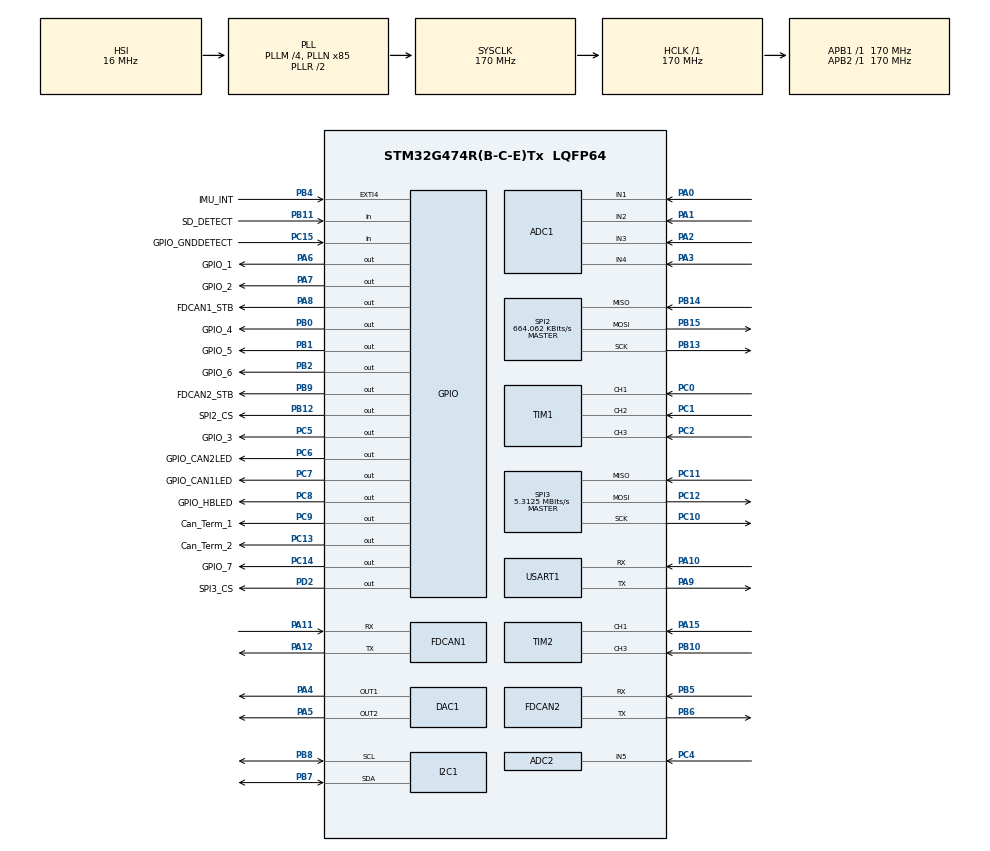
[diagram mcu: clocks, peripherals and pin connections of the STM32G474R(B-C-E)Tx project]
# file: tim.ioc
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ADC1.Channel-0\#ChannelRegularConversion=ADC_CHANNEL_1
ADC1.NbrOfConversionFlag=1
ADC1.OffsetNumber-0\#ChannelRegularConversion=ADC_OFFSET_NONE
ADC1.Rank-0\#ChannelRegularConversion=1
ADC1.SamplingTime-0\#ChannelRegularConversion=ADC_SAMPLETIME_2CYCLES_5
ADC1.master=1
ADC2.Channel-2\#ChannelRegularConversion=ADC_CHANNEL_5
ADC2.NbrOfConversionFlag=1
ADC2.OffsetNumber-2\#ChannelRegularConversion=ADC_OFFSET_NONE
ADC2.Rank-2\#ChannelRegularConversion=1
ADC2.SamplingTime-2\#ChannelRegularConversion=ADC_SAMPLETIME_2CYCLES_5
DAC1.DAC_Channel-DAC_OUT2=DAC_CHANNEL_2
FDCAN1.AutoRetransmission=ENABLE
FDCAN1.CalculateBaudRateNominal=500000
FDCAN1.CalculateTimeBitNominal=2000
FDCAN1.CalculateTimeQuantumNominal=100.0
FDCAN1.DataPrescaler=5
FDCAN1.DataSyncJumpWidth=3
FDCAN1.DataTimeSeg1=13
FDCAN1.DataTimeSeg2=3
FDCAN1.FrameFormat=FDCAN_FRAME_FD_BRS
FDCAN1.NominalPrescaler=17
FDCAN1.NominalSyncJumpWidth=4
FDCAN1.NominalTimeSeg1=15
FDCAN1.NominalTimeSeg2=4
FDCAN2.AutoRetransmission=ENABLE
FDCAN2.CalculateBaudRateNominal=500000
FDCAN2.CalculateTimeBitNominal=2000
FDCAN2.CalculateTimeQuantumNominal=100.0
FDCAN2.DataPrescaler=5
FDCAN2.DataSyncJumpWidth=3
FDCAN2.DataTimeSeg1=13
FDCAN2.DataTimeSeg2=3
FDCAN2.FrameFormat=FDCAN_FRAME_FD_BRS
FDCAN2.NominalPrescaler=17
FDCAN2.NominalSyncJumpWidth=4
FDCAN2.NominalTimeSeg1=15
FDCAN2.NominalTimeSeg2=4
FREERTOS.Tasks01=initTask,24,128,StartDefaultTask,Default,NULL,Dynamic,NULL,NULL
FREERTOS.configTOTAL_HEAP_SIZE=32768
FREERTOS.configUSE_NEWLIB_REENTRANT=1
I2C1.Timing=0x40B285C2
Mcu.Family=STM32G4
Mcu.Name=STM32G474R(B-C-E)Tx
Mcu.Package=LQFP64
NVIC.EXTI4_IRQn=true\:5\:0\:false\:false\:true\:true\:true\:true\:true
NVIC.FDCAN1_IT0_IRQn=true\:5\:0\:false\:false\:true\:true\:true\:true\:true
NVIC.FDCAN1_IT1_IRQn=true\:5\:0\:false\:false\:true\:true\:true\:true\:true
NVIC.FDCAN2_IT0_IRQn=true\:5\:0\:false\:false\:true\:true\:true\:true\:true
NVIC.FDCAN2_IT1_IRQn=true\:5\:0\:false\:false\:true\:true\:true\:true\:true
NVIC.PriorityGroup=NVIC_PRIORITYGROUP_4
NVIC.TIM6_DAC_IRQn=true\:15\:0\:false\:false\:true\:false\:false\:true\:true
NVIC.TimeBase=TIM6_DAC_IRQn
NVIC.TimeBaseIP=TIM6
NVIC.USART1_IRQn=true\:5\:0\:false\:false\:true\:true\:true\:true\:true
PA0.Mode=IN1-Single-Ended
PA0.Signal=ADC1_IN1
PA1.Mode=IN2-Single-Ended
PA1.Signal=ADC1_IN2
PA10.Mode=Asynchronous
PA10.Signal=USART1_RX
PA11.Mode=FDCAN_Activate
PA11.Signal=FDCAN1_RX
PA12.Mode=FDCAN_Activate
PA12.Signal=FDCAN1_TX
PA13.GPIO_Label=SWDIO
PA13.Mode=Trace_Asynchronous_SW
PA13.Signal=SYS_JTMS-SWDIO
PA14.GPIO_Label=SWCLK
PA14.Mode=Trace_Asynchronous_SW
PA14.Signal=SYS_JTCK-SWCLK
PA15.Signal=S_TIM2_CH1
PA2.Mode=IN3-Single-Ended
PA2.Signal=ADC1_IN3
PA3.Mode=IN4-Single-Ended
PA3.Signal=ADC1_IN4
PA4.Signal=COMP_DAC11_group
PA5.Signal=COMP_DAC12_group
PA6.GPIO_Label=GPIO_1
PA6.Signal=GPIO_Output
PA7.GPIO_Label=GPIO_2
PA7.Signal=SharedStack_PA7
PA8.GPIO_Label=FDCAN1_STB
PA8.PinState=GPIO_PIN_SET
PA8.Signal=GPIO_Output
PA9.Mode=Asynchronous
PA9.Signal=USART1_TX
PB0.GPIO_Label=GPIO_4
PB0.Signal=SharedStack_PB0
PB1.GPIO_Label=GPIO_5
PB1.Signal=SharedStack_PB1
PB10.Signal=S_TIM2_CH3
PB11.GPIO_Label=SD_DETECT
PB11.GPIO_PuPd=GPIO_PULLUP
PB11.Signal=GPIO_Input
PB12.GPIO_Label=SPI2_CS
PB12.PinState=GPIO_PIN_SET
PB12.Signal=GPIO_Output
PB13.Mode=Full_Duplex_Master
PB13.Signal=SPI2_SCK
PB14.Mode=Full_Duplex_Master
PB14.Signal=SPI2_MISO
PB15.Mode=Full_Duplex_Master
PB15.Signal=SPI2_MOSI
PB2.GPIO_Label=GPIO_6
PB2.Signal=SharedStack_PB2
PB3.GPIO_Label=SWO
PB3.Mode=Trace_Asynchronous_SW
PB3.Signal=SYS_JTDO-SWO
PB4.GPIO_Label=IMU_INT
PB4.Signal=GPXTI4
PB5.Mode=FDCAN_Activate
PB5.Signal=FDCAN2_RX
PB6.Mode=FDCAN_Activate
PB6.Signal=FDCAN2_TX
PB7.Mode=I2C
PB7.Signal=I2C1_SDA
PB8-BOOT0.Mode=I2C
PB8-BOOT0.Signal=I2C1_SCL
PB9.GPIO_Label=FDCAN2_STB
PB9.PinState=GPIO_PIN_SET
PB9.Signal=GPIO_Output
PC0.Signal=S_TIM1_CH1
PC1.Signal=S_TIM1_CH2
PC10.Mode=Full_Duplex_Master
PC10.Signal=SPI3_SCK
PC11.Mode=Full_Duplex_Master
PC11.Signal=SPI3_MISO
PC12.Mode=Full_Duplex_Master
PC12.Signal=SPI3_MOSI
PC13.GPIO_Label=Can_Term_2
PC13.Signal=GPIO_Output
PC14-OSC32_IN.GPIO_Label=GPIO_7
PC14-OSC32_IN.Signal=GPIO_Output
PC15-OSC32_OUT.GPIO_Label=GPIO_GNDDETECT
PC15-OSC32_OUT.GPIO_PuPd=GPIO_PULLUP
PC15-OSC32_OUT.Signal=GPIO_Input
PC2.Signal=S_TIM1_CH3
PC3.GPIO_Label=VBAT_ADC
PC3.Signal=ADC1_IN9
PC4.Mode=IN5-Single-Ended
PC4.Signal=ADC2_IN5
PC5.GPIO_Label=GPIO_3
PC5.Signal=SharedStack_PC5
PC6.GPIO_Label=GPIO_CAN2LED
PC6.GPIO_ModeDefaultOutputPP=GPIO_MODE_OUTPUT_PP
PC6.GPIO_PuPd=GPIO_NOPULL
PC6.PinState=GPIO_PIN_SET
PC6.Signal=GPIO_Output
PC7.GPIO_Label=GPIO_CAN1LED
PC7.GPIO_ModeDefaultOutputPP=GPIO_MODE_OUTPUT_PP
PC7.GPIO_PuPd=GPIO_NOPULL
PC7.PinState=GPIO_PIN_SET
PC7.Signal=GPIO_Output
PC8.GPIO_Label=GPIO_HBLED
PC8.GPIO_ModeDefaultOutputPP=GPIO_MODE_OUTPUT_PP
PC8.GPIO_PuPd=GPIO_NOPULL
PC8.PinState=GPIO_PIN_SET
PC8.Signal=GPIO_Output
PC9.GPIO_Label=Can_Term_1
PC9.Signal=GPIO_Output
PD2.GPIO_Label=SPI3_CS
PD2.PinState=GPIO_PIN_SET
PD2.Signal=GPIO_Output
PF0-OSC_IN.Mode=HSE-External-Oscillator
PF0-OSC_IN.Signal=RCC_OSC_IN
PF1-OSC_OUT.Mode=HSE-External-Oscillator
PF1-OSC_OUT.Signal=RCC_OSC_OUT
ProjectManager.HeapSize=0x200
ProjectManager.StackSize=0x400
ProjectManager.TargetToolchain=CMake
RCC.ADC12Freq_Value=170000000
RCC.ADC345Freq_Value=170000000
RCC.AHBFreq_Value=170000000
RCC.APB1Freq_Value=170000000
RCC.APB1TimFreq_Value=170000000
RCC.APB2Freq_Value=170000000
RCC.APB2TimFreq_Value=170000000
RCC.CortexFreq_Value=170000000
RCC.EXTERNAL_CLOCK_VALUE=12288000
RCC.HCLKFreq_Value=170000000
RCC.HSE_VALUE=8000000
RCC.HSI48_VALUE=48000000
RCC.HSI_VALUE=16000000
RCC.LSE_VALUE=32768
RCC.PLLM=RCC_PLLM_DIV4
RCC.PLLN=85
RCC.SYSCLKFreq_VALUE=170000000
RCC.SYSCLKSource=RCC_SYSCLKSOURCE_PLLCLK
RCC.USBFreq_Value=170000000
RCC.VCOOutputFreq_Value=340000000
SH.COMP_DAC11_group.0=DAC1_OUT1,DAC_OUT1
SH.COMP_DAC12_group.0=DAC1_OUT2,DAC_OUT2
SH.S_TIM1_CH1.0=TIM1_CH1,Encoder_Interface
SH.S_TIM1_CH2.0=TIM1_CH2,Encoder_Interface
SH.S_TIM1_CH3.0=TIM1_CH3,Input_Capture3_from_TI3
SH.S_TIM2_CH1.0=TIM2_CH1,Input_Capture1_from_TI1
SH.S_TIM2_CH3.0=TIM2_CH3,Input_Capture3_from_TI3
SH.SharedStack_PA7.0=GPIO_Output
SH.SharedStack_PB0.0=GPIO_Output
SH.SharedStack_PB1.0=GPIO_Output
SH.SharedStack_PB2.0=GPIO_Output
SH.SharedStack_PC5.0=GPIO_Output
SPI2.BaudRatePrescaler=SPI_BAUDRATEPRESCALER_256
SPI2.CalculateBaudRate=664.062 KBits/s
SPI2.DataSize=SPI_DATASIZE_8BIT
SPI2.Direction=SPI_DIRECTION_2LINES
SPI2.Mode=SPI_MODE_MASTER
SPI2.VirtualType=VM_MASTER
SPI3.BaudRatePrescaler=SPI_BAUDRATEPRESCALER_32
SPI3.CLKPhase=SPI_PHASE_2EDGE
SPI3.CLKPolarity=SPI_POLARITY_HIGH
SPI3.CalculateBaudRate=5.3125 MBits/s
SPI3.DataSize=SPI_DATASIZE_8BIT
SPI3.Direction=SPI_DIRECTION_2LINES
SPI3.Mode=SPI_MODE_MASTER
SPI3.VirtualType=VM_MASTER
TIM1.Channel-Input_Capture3_from_TI3=TIM_CHANNEL_3
TIM2.Channel-Input_Capture1_from_TI1=TIM_CHANNEL_1
TIM2.Channel-Input_Capture3_from_TI3=TIM_CHANNEL_3
USART1.VirtualMode-Asynchronous=VM_ASYNC
VP_FATFS_VS_Generic.Mode=User_defined
VP_FREERTOS_VS_CMSIS_V2.Mode=CMSIS_V2
VP_SYS_VS_DBSignals.Mode=DisableDeadBatterySignals
VP_SYS_VS_tim6.Mode=TIM6
board=custom

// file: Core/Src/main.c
/* USER CODE BEGIN Header */
/**
  ******************************************************************************
  * @file           : main.c
  * @brief          : Main program body
  ******************************************************************************
  * @attention
  *
  * Copyright (c) 2026 STMicroelectronics.
  * All rights reserved.
  *
  * This software is licensed under terms that can be found in the LICENSE file
  * in the root directory of this software component.
  * If no LICENSE file comes with this software, it is provided AS-IS.
  *
  ******************************************************************************
  */
/* USER CODE END Header */
#include "main.h"
#include "cmsis_os.h"
#include "app_fatfs.h"

/* USER CODE BEGIN Includes */
#include "tasks.h"
/* USER CODE END Includes */

ADC_HandleTypeDef hadc1;
ADC_HandleTypeDef hadc2;

DAC_HandleTypeDef hdac1;

FDCAN_HandleTypeDef hfdcan1;
FDCAN_HandleTypeDef hfdcan2;

I2C_HandleTypeDef hi2c1;

SPI_HandleTypeDef hspi2;
SPI_HandleTypeDef hspi3;

TIM_HandleTypeDef htim1;
TIM_HandleTypeDef htim2;

UART_HandleTypeDef huart1;

/* Definitions for initTask */
osThreadId_t initTaskHandle;
const osThreadAttr_t initTask_attributes = {
  .name = "initTask",
  .priority = (osPriority_t) osPriorityNormal,
  .stack_size = 128 * 4
};

void SystemClock_Config(void);
static void MX_GPIO_Init(void);
static void MX_ADC1_Init(void);
static void MX_ADC2_Init(void);
static void MX_DAC1_Init(void);
static void MX_FDCAN1_Init(void);
static void MX_FDCAN2_Init(void);
static void MX_I2C1_Init(void);
static void MX_SPI2_Init(void);
static void MX_SPI3_Init(void);
static void MX_TIM1_Init(void);
static void MX_TIM2_Init(void);
static void MX_USART1_UART_Init(void);
void StartDefaultTask(void *argument);

int main(void)
{

  /* MCU Configuration--------------------------------------------------------*/

  /* Reset of all peripherals, Initializes the Flash interface and the Systick. */
  HAL_Init();

  /* Configure the system clock */
  SystemClock_Config();

  /* Initialize all configured peripherals */
  MX_GPIO_Init();
  MX_ADC1_Init();
  MX_ADC2_Init();
  MX_DAC1_Init();
  MX_FDCAN1_Init();
  MX_FDCAN2_Init();
  MX_I2C1_Init();
  MX_SPI2_Init();
  MX_SPI3_Init();
  MX_TIM1_Init();
  MX_TIM2_Init();
  MX_USART1_UART_Init();
  if (MX_FATFS_Init() != APP_OK) {
    Error_Handler();
  }

  /* Init scheduler */
  osKernelInitialize();

  /* Create the thread(s) */
  /* creation of initTask */
  initTaskHandle = osThreadNew(StartDefaultTask, NULL, &initTask_attributes);

  /* Start scheduler */
  osKernelStart();

  /* We should never get here as control is now taken by the scheduler */

  /* Infinite loop */
  while (1)
  {

  }
}

void SystemClock_Config(void)
{
  RCC_OscInitTypeDef RCC_OscInitStruct = {0};
  RCC_ClkInitTypeDef RCC_ClkInitStruct = {0};

  /** Configure the main internal regulator output voltage
  */
  HAL_PWREx_ControlVoltageScaling(PWR_REGULATOR_VOLTAGE_SCALE1_BOOST);

  /** Initializes the RCC Oscillators according to the specified parameters
  * in the RCC_OscInitTypeDef structure.
  */
  RCC_OscInitStruct.OscillatorType = RCC_OSCILLATORTYPE_HSI;
  RCC_OscInitStruct.HSIState = RCC_HSI_ON;
  RCC_OscInitStruct.HSICalibrationValue = RCC_HSICALIBRATION_DEFAULT;
  RCC_OscInitStruct.PLL.PLLState = RCC_PLL_ON;
  RCC_OscInitStruct.PLL.PLLSource = RCC_PLLSOURCE_HSI;
  RCC_OscInitStruct.PLL.PLLM = RCC_PLLM_DIV4;
  RCC_OscInitStruct.PLL.PLLN = 85;
  RCC_OscInitStruct.PLL.PLLP = RCC_PLLP_DIV2;
  RCC_OscInitStruct.PLL.PLLQ = RCC_PLLQ_DIV2;
  RCC_OscInitStruct.PLL.PLLR = RCC_PLLR_DIV2;
  if (HAL_RCC_OscConfig(&RCC_OscInitStruct) != HAL_OK)
  {
    Error_Handler();
  }

  /** Initializes the CPU, AHB and APB buses clocks
  */
  RCC_ClkInitStruct.ClockType = RCC_CLOCKTYPE_HCLK|RCC_CLOCKTYPE_SYSCLK
                              |RCC_CLOCKTYPE_PCLK1|RCC_CLOCKTYPE_PCLK2;
  RCC_ClkInitStruct.SYSCLKSource = RCC_SYSCLKSOURCE_PLLCLK;
  RCC_ClkInitStruct.AHBCLKDivider = RCC_SYSCLK_DIV1;
  RCC_ClkInitStruct.APB1CLKDivider = RCC_HCLK_DIV1;
  RCC_ClkInitStruct.APB2CLKDivider = RCC_HCLK_DIV1;

  if (HAL_RCC_ClockConfig(&RCC_ClkInitStruct, FLASH_LATENCY_4) != HAL_OK)
  {
    Error_Handler();
  }
}

static void MX_ADC1_Init(void)
{

  ADC_MultiModeTypeDef multimode = {0};
  ADC_ChannelConfTypeDef sConfig = {0};

  /** Common config
  */
  hadc1.Instance = ADC1;
  hadc1.Init.ClockPrescaler = ADC_CLOCK_SYNC_PCLK_DIV4;
  hadc1.Init.Resolution = ADC_RESOLUTION_12B;
  hadc1.Init.DataAlign = ADC_DATAALIGN_RIGHT;
  hadc1.Init.GainCompensation = 0;
  hadc1.Init.ScanConvMode = ADC_SCAN_DISABLE;
  hadc1.Init.EOCSelection = ADC_EOC_SINGLE_CONV;
  hadc1.Init.LowPowerAutoWait = DISABLE;
  hadc1.Init.ContinuousConvMode = DISABLE;
  hadc1.Init.NbrOfConversion = 1;
  hadc1.Init.DiscontinuousConvMode = DISABLE;
  hadc1.Init.ExternalTrigConv = ADC_SOFTWARE_START;
  hadc1.Init.ExternalTrigConvEdge = ADC_EXTERNALTRIGCONVEDGE_NONE;
  hadc1.Init.DMAContinuousRequests = DISABLE;
  hadc1.Init.Overrun = ADC_OVR_DATA_PRESERVED;
  hadc1.Init.OversamplingMode = DISABLE;
  if (HAL_ADC_Init(&hadc1) != HAL_OK)
  {
    Error_Handler();
  }

  /** Configure the ADC multi-mode
  */
  multimode.Mode = ADC_MODE_INDEPENDENT;
  if (HAL_ADCEx_MultiModeConfigChannel(&hadc1, &multimode) != HAL_OK)
  {
    Error_Handler();
  }

  /** Configure Regular Channel
  */
  sConfig.Channel = ADC_CHANNEL_1;
  sConfig.Rank = ADC_REGULAR_RANK_1;
  sConfig.SamplingTime = ADC_SAMPLETIME_2CYCLES_5;
  sConfig.SingleDiff = ADC_SINGLE_ENDED;
  sConfig.OffsetNumber = ADC_OFFSET_NONE;
  sConfig.Offset = 0;
  if (HAL_ADC_ConfigChannel(&hadc1, &sConfig) != HAL_OK)
  {
    Error_Handler();
  }

}

static void MX_ADC2_Init(void)
{

  ADC_ChannelConfTypeDef sConfig = {0};

  /** Common config
  */
  hadc2.Instance = ADC2;
  hadc2.Init.ClockPrescaler = ADC_CLOCK_SYNC_PCLK_DIV4;
  hadc2.Init.Resolution = ADC_RESOLUTION_12B;
  hadc2.Init.DataAlign = ADC_DATAALIGN_RIGHT;
  hadc2.Init.GainCompensation = 0;
  hadc2.Init.ScanConvMode = ADC_SCAN_DISABLE;
  hadc2.Init.EOCSelection = ADC_EOC_SINGLE_CONV;
  hadc2.Init.LowPowerAutoWait = DISABLE;
  hadc2.Init.ContinuousConvMode = DISABLE;
  hadc2.Init.NbrOfConversion = 1;
  hadc2.Init.DiscontinuousConvMode = DISABLE;
  hadc2.Init.ExternalTrigConv = ADC_SOFTWARE_START;
  hadc2.Init.ExternalTrigConvEdge = ADC_EXTERNALTRIGCONVEDGE_NONE;
  hadc2.Init.DMAContinuousRequests = DISABLE;
  hadc2.Init.Overrun = ADC_OVR_DATA_PRESERVED;
  hadc2.Init.OversamplingMode = DISABLE;
  if (HAL_ADC_Init(&hadc2) != HAL_OK)
  {
    Error_Handler();
  }

  /** Configure Regular Channel
  */
  sConfig.Channel = ADC_CHANNEL_5;
  sConfig.Rank = ADC_REGULAR_RANK_1;
  sConfig.SamplingTime = ADC_SAMPLETIME_2CYCLES_5;
  sConfig.SingleDiff = ADC_SINGLE_ENDED;
  sConfig.OffsetNumber = ADC_OFFSET_NONE;
  sConfig.Offset = 0;
  if (HAL_ADC_ConfigChannel(&hadc2, &sConfig) != HAL_OK)
  {
    Error_Handler();
  }

}

static void MX_DAC1_Init(void)
{

  DAC_ChannelConfTypeDef sConfig = {0};

  /** DAC Initialization
  */
  hdac1.Instance = DAC1;
  if (HAL_DAC_Init(&hdac1) != HAL_OK)
  {
    Error_Handler();
  }

  /** DAC channel OUT1 config
  */
  sConfig.DAC_HighFrequency = DAC_HIGH_FREQUENCY_INTERFACE_MODE_AUTOMATIC;
  sConfig.DAC_DMADoubleDataMode = DISABLE;
  sConfig.DAC_SignedFormat = DISABLE;
  sConfig.DAC_SampleAndHold = DAC_SAMPLEANDHOLD_DISABLE;
  sConfig.DAC_Trigger = DAC_TRIGGER_NONE;
  sConfig.DAC_Trigger2 = DAC_TRIGGER_NONE;
  sConfig.DAC_OutputBuffer = DAC_OUTPUTBUFFER_ENABLE;
  sConfig.DAC_ConnectOnChipPeripheral = DAC_CHIPCONNECT_EXTERNAL;
  sConfig.DAC_UserTrimming = DAC_TRIMMING_FACTORY;
  if (HAL_DAC_ConfigChannel(&hdac1, &sConfig, DAC_CHANNEL_1) != HAL_OK)
  {
    Error_Handler();
  }

  /** DAC channel OUT2 config
  */
  if (HAL_DAC_ConfigChannel(&hdac1, &sConfig, DAC_CHANNEL_2) != HAL_OK)
  {
    Error_Handler();
  }

}

static void MX_FDCAN1_Init(void)
{

  hfdcan1.Instance = FDCAN1;
  hfdcan1.Init.ClockDivider = FDCAN_CLOCK_DIV1;
  hfdcan1.Init.FrameFormat = FDCAN_FRAME_FD_BRS;
  hfdcan1.Init.Mode = FDCAN_MODE_NORMAL;
  hfdcan1.Init.AutoRetransmission = ENABLE;
  hfdcan1.Init.TransmitPause = DISABLE;
  hfdcan1.Init.ProtocolException = DISABLE;
  hfdcan1.Init.NominalPrescaler = 17;
  hfdcan1.Init.NominalSyncJumpWidth = 4;
  hfdcan1.Init.NominalTimeSeg1 = 15;
  hfdcan1.Init.NominalTimeSeg2 = 4;
  hfdcan1.Init.DataPrescaler = 5;
  hfdcan1.Init.DataSyncJumpWidth = 3;
  hfdcan1.Init.DataTimeSeg1 = 13;
  hfdcan1.Init.DataTimeSeg2 = 3;
  hfdcan1.Init.StdFiltersNbr = 0;
  hfdcan1.Init.ExtFiltersNbr = 0;
  hfdcan1.Init.TxFifoQueueMode = FDCAN_TX_FIFO_OPERATION;
  if (HAL_FDCAN_Init(&hfdcan1) != HAL_OK)
  {
    Error_Handler();
  }

}

static void MX_FDCAN2_Init(void)
{

  hfdcan2.Instance = FDCAN2;
  hfdcan2.Init.ClockDivider = FDCAN_CLOCK_DIV1;
  hfdcan2.Init.FrameFormat = FDCAN_FRAME_FD_BRS;
  hfdcan2.Init.Mode = FDCAN_MODE_NORMAL;
  hfdcan2.Init.AutoRetransmission = ENABLE;
  hfdcan2.Init.TransmitPause = DISABLE;
  hfdcan2.Init.ProtocolException = DISABLE;
  hfdcan2.Init.NominalPrescaler = 17;
  hfdcan2.Init.NominalSyncJumpWidth = 4;
  hfdcan2.Init.NominalTimeSeg1 = 15;
  hfdcan2.Init.NominalTimeSeg2 = 4;
  hfdcan2.Init.DataPrescaler = 5;
  hfdcan2.Init.DataSyncJumpWidth = 3;
  hfdcan2.Init.DataTimeSeg1 = 13;
  hfdcan2.Init.DataTimeSeg2 = 3;
  hfdcan2.Init.StdFiltersNbr = 0;
  hfdcan2.Init.ExtFiltersNbr = 0;
  hfdcan2.Init.TxFifoQueueMode = FDCAN_TX_FIFO_OPERATION;
  if (HAL_FDCAN_Init(&hfdcan2) != HAL_OK)
  {
    Error_Handler();
  }

}

static void MX_I2C1_Init(void)
{

  hi2c1.Instance = I2C1;
  hi2c1.Init.Timing = 0x40B285C2;
  hi2c1.Init.OwnAddress1 = 0;
  hi2c1.Init.AddressingMode = I2C_ADDRESSINGMODE_7BIT;
  hi2c1.Init.DualAddressMode = I2C_DUALADDRESS_DISABLE;
  hi2c1.Init.OwnAddress2 = 0;
  hi2c1.Init.OwnAddress2Masks = I2C_OA2_NOMASK;
  hi2c1.Init.GeneralCallMode = I2C_GENERALCALL_DISABLE;
  hi2c1.Init.NoStretchMode = I2C_NOSTRETCH_DISABLE;
  if (HAL_I2C_Init(&hi2c1) != HAL_OK)
  {
    Error_Handler();
  }

  /** Configure Analogue filter
  */
  if (HAL_I2CEx_ConfigAnalogFilter(&hi2c1, I2C_ANALOGFILTER_ENABLE) != HAL_OK)
  {
    Error_Handler();
  }

  /** Configure Digital filter
  */
  if (HAL_I2CEx_ConfigDigitalFilter(&hi2c1, 0) != HAL_OK)
  {
    Error_Handler();
  }

}

static void MX_SPI2_Init(void)
{

  /* SPI2 parameter configuration*/
  hspi2.Instance = SPI2;
  hspi2.Init.Mode = SPI_MODE_MASTER;
  hspi2.Init.Direction = SPI_DIRECTION_2LINES;
  hspi2.Init.DataSize = SPI_DATASIZE_8BIT;
  hspi2.Init.CLKPolarity = SPI_POLARITY_LOW;
  hspi2.Init.CLKPhase = SPI_PHASE_1EDGE;
  hspi2.Init.NSS = SPI_NSS_SOFT;
  hspi2.Init.BaudRatePrescaler = SPI_BAUDRATEPRESCALER_256;
  hspi2.Init.FirstBit = SPI_FIRSTBIT_MSB;
  hspi2.Init.TIMode = SPI_TIMODE_DISABLE;
  hspi2.Init.CRCCalculation = SPI_CRCCALCULATION_DISABLE;
  hspi2.Init.CRCPolynomial = 7;
  hspi2.Init.CRCLength = SPI_CRC_LENGTH_DATASIZE;
  hspi2.Init.NSSPMode = SPI_NSS_PULSE_ENABLE;
  if (HAL_SPI_Init(&hspi2) != HAL_OK)
  {
    Error_Handler();
  }

}

static void MX_SPI3_Init(void)
{

  /* SPI3 parameter configuration*/
  hspi3.Instance = SPI3;
  hspi3.Init.Mode = SPI_MODE_MASTER;
  hspi3.Init.Direction = SPI_DIRECTION_2LINES;
  hspi3.Init.DataSize = SPI_DATASIZE_8BIT;
  hspi3.Init.CLKPolarity = SPI_POLARITY_HIGH;
  hspi3.Init.CLKPhase = SPI_PHASE_2EDGE;
  hspi3.Init.NSS = SPI_NSS_SOFT;
  hspi3.Init.BaudRatePrescaler = SPI_BAUDRATEPRESCALER_32;
  hspi3.Init.FirstBit = SPI_FIRSTBIT_MSB;
  hspi3.Init.TIMode = SPI_TIMODE_DISABLE;
  hspi3.Init.CRCCalculation = SPI_CRCCALCULATION_DISABLE;
  hspi3.Init.CRCPolynomial = 7;
  hspi3.Init.CRCLength = SPI_CRC_LENGTH_DATASIZE;
  hspi3.Init.NSSPMode = SPI_NSS_PULSE_DISABLE;
  if (HAL_SPI_Init(&hspi3) != HAL_OK)
  {
    Error_Handler();
  }

}

static void MX_TIM1_Init(void)
{

  TIM_Encoder_InitTypeDef sConfig = {0};
  TIM_MasterConfigTypeDef sMasterConfig = {0};
  TIM_IC_InitTypeDef sConfigIC = {0};

  htim1.Instance = TIM1;
  htim1.Init.Prescaler = 0;
  htim1.Init.CounterMode = TIM_COUNTERMODE_UP;
  htim1.Init.Period = 65535;
  htim1.Init.ClockDivision = TIM_CLOCKDIVISION_DIV1;
  htim1.Init.RepetitionCounter = 0;
  htim1.Init.AutoReloadPreload = TIM_AUTORELOAD_PRELOAD_DISABLE;
  if (HAL_TIM_IC_Init(&htim1) != HAL_OK)
  {
    Error_Handler();
  }
  sConfig.EncoderMode = TIM_ENCODERMODE_TI1;
  sConfig.IC1Polarity = TIM_ICPOLARITY_RISING;
  sConfig.IC1Selection = TIM_ICSELECTION_DIRECTTI;
  sConfig.IC1Prescaler = TIM_ICPSC_DIV1;
  sConfig.IC1Filter = 0;
  sConfig.IC2Polarity = TIM_ICPOLARITY_RISING;
  sConfig.IC2Selection = TIM_ICSELECTION_DIRECTTI;
  sConfig.IC2Prescaler = TIM_ICPSC_DIV1;
  sConfig.IC2Filter = 0;
  if (HAL_TIM_Encoder_Init(&htim1, &sConfig) != HAL_OK)
  {
    Error_Handler();
  }
  sMasterConfig.MasterOutputTrigger = TIM_TRGO_RESET;
  sMasterConfig.MasterOutputTrigger2 = TIM_TRGO2_RESET;
  sMasterConfig.MasterSlaveMode = TIM_MASTERSLAVEMODE_DISABLE;
  if (HAL_TIMEx_MasterConfigSynchronization(&htim1, &sMasterConfig) != HAL_OK)
  {
    Error_Handler();
  }
  sConfigIC.ICPolarity = TIM_INPUTCHANNELPOLARITY_RISING;
  sConfigIC.ICSelection = TIM_ICSELECTION_DIRECTTI;
  sConfigIC.ICPrescaler = TIM_ICPSC_DIV1;
  sConfigIC.ICFilter = 0;
  if (HAL_TIM_IC_ConfigChannel(&htim1, &sConfigIC, TIM_CHANNEL_3) != HAL_OK)
  {
    Error_Handler();
  }

}

static void MX_TIM2_Init(void)
{

  TIM_MasterConfigTypeDef sMasterConfig = {0};
  TIM_IC_InitTypeDef sConfigIC = {0};

  htim2.Instance = TIM2;
  htim2.Init.Prescaler = 0;
  htim2.Init.CounterMode = TIM_COUNTERMODE_UP;
  htim2.Init.Period = 4294967295;
  htim2.Init.ClockDivision = TIM_CLOCKDIVISION_DIV1;
  htim2.Init.AutoReloadPreload = TIM_AUTORELOAD_PRELOAD_DISABLE;
  if (HAL_TIM_IC_Init(&htim2) != HAL_OK)
  {
    Error_Handler();
  }
  sMasterConfig.MasterOutputTrigger = TIM_TRGO_RESET;
  sMasterConfig.MasterSlaveMode = TIM_MASTERSLAVEMODE_DISABLE;
  if (HAL_TIMEx_MasterConfigSynchronization(&htim2, &sMasterConfig) != HAL_OK)
  {
    Error_Handler();
  }
  sConfigIC.ICPolarity = TIM_INPUTCHANNELPOLARITY_RISING;
  sConfigIC.ICSelection = TIM_ICSELECTION_DIRECTTI;
  sConfigIC.ICPrescaler = TIM_ICPSC_DIV1;
  sConfigIC.ICFilter = 0;
  if (HAL_TIM_IC_ConfigChannel(&htim2, &sConfigIC, TIM_CHANNEL_1) != HAL_OK)
  {
    Error_Handler();
  }
  if (HAL_TIM_IC_ConfigChannel(&htim2, &sConfigIC, TIM_CHANNEL_3) != HAL_OK)
  {
    Error_Handler();
  }

}

static void MX_USART1_UART_Init(void)
{

  huart1.Instance = USART1;
  huart1.Init.BaudRate = 115200;
  huart1.Init.WordLength = UART_WORDLENGTH_8B;
  huart1.Init.StopBits = UART_STOPBITS_1;
  huart1.Init.Parity = UART_PARITY_NONE;
  huart1.Init.Mode = UART_MODE_TX_RX;
  huart1.Init.HwFlowCtl = UART_HWCONTROL_NONE;
  huart1.Init.OverSampling = UART_OVERSAMPLING_16;
  huart1.Init.OneBitSampling = UART_ONE_BIT_SAMPLE_DISABLE;
  huart1.Init.ClockPrescaler = UART_PRESCALER_DIV1;
  huart1.AdvancedInit.AdvFeatureInit = UART_ADVFEATURE_NO_INIT;
  if (HAL_UART_Init(&huart1) != HAL_OK)
  {
    Error_Handler();
  }
  if (HAL_UARTEx_SetTxFifoThreshold(&huart1, UART_TXFIFO_THRESHOLD_1_8) != HAL_OK)
  {
    Error_Handler();
  }
  if (HAL_UARTEx_SetRxFifoThreshold(&huart1, UART_RXFIFO_THRESHOLD_1_8) != HAL_OK)
  {
    Error_Handler();
  }
  if (HAL_UARTEx_DisableFifoMode(&huart1) != HAL_OK)
  {
    Error_Handler();
  }

}

static void MX_GPIO_Init(void)
{
  GPIO_InitTypeDef GPIO_InitStruct = {0};

  /* GPIO Ports Clock Enable */
  __HAL_RCC_GPIOC_CLK_ENABLE();
  __HAL_RCC_GPIOF_CLK_ENABLE();
  __HAL_RCC_GPIOA_CLK_ENABLE();
  __HAL_RCC_GPIOB_CLK_ENABLE();
  __HAL_RCC_GPIOD_CLK_ENABLE();

  /*Configure GPIO pin Output Level */
  HAL_GPIO_WritePin(GPIOC, Can_Term_2_Pin|GPIO_7_Pin|Can_Term_1_Pin, GPIO_PIN_RESET);

  /*Configure GPIO pin Output Level */
  HAL_GPIO_WritePin(GPIO_1_GPIO_Port, GPIO_1_Pin, GPIO_PIN_RESET);

  /*Configure GPIO pin Output Level */
  HAL_GPIO_WritePin(GPIOB, SPI2_CS_Pin|FDCAN2_STB_Pin, GPIO_PIN_SET);

  /*Configure GPIO pin Output Level */
  HAL_GPIO_WritePin(GPIOC, GPIO_CAN2LED_Pin|GPIO_CAN1LED_Pin|GPIO_HBLED_Pin, GPIO_PIN_SET);

  /*Configure GPIO pin Output Level */
  HAL_GPIO_WritePin(FDCAN1_STB_GPIO_Port, FDCAN1_STB_Pin, GPIO_PIN_SET);

  /*Configure GPIO pin Output Level */
  HAL_GPIO_WritePin(SPI3_CS_GPIO_Port, SPI3_CS_Pin, GPIO_PIN_SET);

  /*Configure GPIO pins : Can_Term_2_Pin GPIO_7_Pin GPIO_CAN2LED_Pin GPIO_CAN1LED_Pin
                           GPIO_HBLED_Pin Can_Term_1_Pin */
  GPIO_InitStruct.Pin = Can_Term_2_Pin|GPIO_7_Pin|GPIO_CAN2LED_Pin|GPIO_CAN1LED_Pin
                          |GPIO_HBLED_Pin|Can_Term_1_Pin;
  GPIO_InitStruct.Mode = GPIO_MODE_OUTPUT_PP;
  GPIO_InitStruct.Pull = GPIO_NOPULL;
  GPIO_InitStruct.Speed = GPIO_SPEED_FREQ_LOW;
  HAL_GPIO_Init(GPIOC, &GPIO_InitStruct);

  /*Configure GPIO pin : GPIO_GNDDETECT_Pin */
  GPIO_InitStruct.Pin = GPIO_GNDDETECT_Pin;
  GPIO_InitStruct.Mode = GPIO_MODE_INPUT;
  GPIO_InitStruct.Pull = GPIO_PULLUP;
  HAL_GPIO_Init(GPIO_GNDDETECT_GPIO_Port, &GPIO_InitStruct);

  /*Configure GPIO pins : GPIO_1_Pin FDCAN1_STB_Pin */
  GPIO_InitStruct.Pin = GPIO_1_Pin|FDCAN1_STB_Pin;
  GPIO_InitStruct.Mode = GPIO_MODE_OUTPUT_PP;
  GPIO_InitStruct.Pull = GPIO_NOPULL;
  GPIO_InitStruct.Speed = GPIO_SPEED_FREQ_LOW;
  HAL_GPIO_Init(GPIOA, &GPIO_InitStruct);

  /*Configure GPIO pin : SD_DETECT_Pin */
  GPIO_InitStruct.Pin = SD_DETECT_Pin;
  GPIO_InitStruct.Mode = GPIO_MODE_INPUT;
  GPIO_InitStruct.Pull = GPIO_PULLUP;
  HAL_GPIO_Init(SD_DETECT_GPIO_Port, &GPIO_InitStruct);

  /*Configure GPIO pins : SPI2_CS_Pin FDCAN2_STB_Pin */
  GPIO_InitStruct.Pin = SPI2_CS_Pin|FDCAN2_STB_Pin;
  GPIO_InitStruct.Mode = GPIO_MODE_OUTPUT_PP;
  GPIO_InitStruct.Pull = GPIO_NOPULL;
  GPIO_InitStruct.Speed = GPIO_SPEED_FREQ_LOW;
  HAL_GPIO_Init(GPIOB, &GPIO_InitStruct);

  /*Configure GPIO pin : SPI3_CS_Pin */
  GPIO_InitStruct.Pin = SPI3_CS_Pin;
  GPIO_InitStruct.Mode = GPIO_MODE_OUTPUT_PP;
  GPIO_InitStruct.Pull = GPIO_NOPULL;
  GPIO_InitStruct.Speed = GPIO_SPEED_FREQ_LOW;
  HAL_GPIO_Init(SPI3_CS_GPIO_Port, &GPIO_InitStruct);

  /*Configure GPIO pin : IMU_INT_Pin */
  GPIO_InitStruct.Pin = IMU_INT_Pin;
  GPIO_InitStruct.Mode = GPIO_MODE_IT_RISING;
  GPIO_InitStruct.Pull = GPIO_NOPULL;
  HAL_GPIO_Init(IMU_INT_GPIO_Port, &GPIO_InitStruct);

  /* EXTI interrupt init*/
  HAL_NVIC_SetPriority(EXTI4_IRQn, 5, 0);
  HAL_NVIC_EnableIRQ(EXTI4_IRQn);

}

void StartDefaultTask(void *argument)
{
  /* USER CODE BEGIN 5 */
  tasks_init();
  osThreadTerminate(osThreadGetId());
  /* USER CODE END 5 */
}

void HAL_TIM_PeriodElapsedCallback(TIM_HandleTypeDef *htim)
{
  if (htim->Instance == TIM6)
  {
    HAL_IncTick();
  }
}

void Error_Handler(void)
{
  __disable_irq();
  while (1)
  {
  }
}
